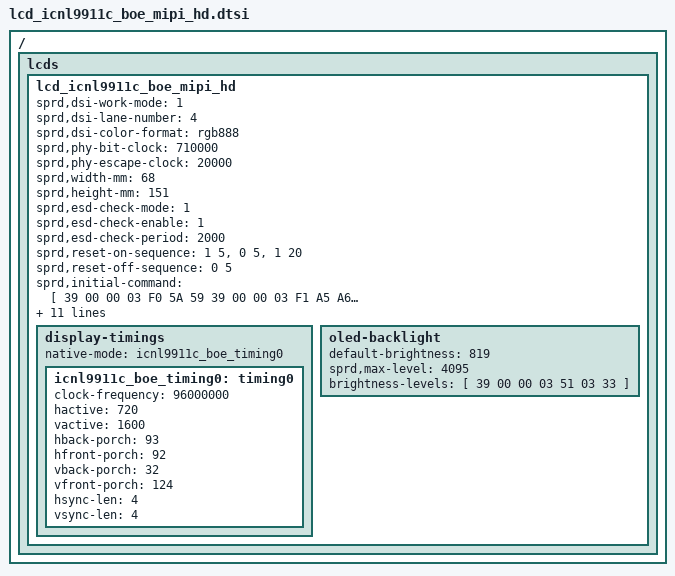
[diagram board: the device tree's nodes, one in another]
/ {
	fragment {
		target-path = "/";
		__overlay__ {
			lcds {
				lcd_icnl9911c_boe_mipi_hd: lcd_icnl9911c_boe_mipi_hd {
					sprd,dsi-work-mode = <1>; /* video burst mode*/
					sprd,dsi-lane-number = <4>;
					sprd,dsi-color-format = "rgb888";

					sprd,phy-bit-clock = <710000>;  /* kbps */
					sprd,phy-escape-clock = <20000>;/* kHz */

					sprd,width-mm = <68>;
					sprd,height-mm = <151>;

					sprd,esd-check-mode = <1>;
					sprd,esd-check-enable = <1>;
					sprd,esd-check-period = <2000>;

					sprd,reset-on-sequence = <1 5>, <0 5>, <1 20>;
					sprd,reset-off-sequence = <0 5>;

					sprd,initial-command = [
						39 00 00 03 F0 5A 59
						39 00 00 03 F1 A5 A6
						39 00 00 1F B0 83 82 05 04 02 03 04 05 11 11 11 11 00 00 00 78 00 00 0F 05 04 03 02 01 02 03 04 04 00 00
						39 00 00 21 B1 B0 02 89 80 05 00 00 79 00 00 04 08 54 00 00 00 44 40 02 01 40 02 01 40 02 01 40 02 01 00 00 00
						39 00 00 1D B4 00 01 01 05 DD DC 01 01 E3 00 00 0F 0D DD 00 00 00 00 00 00 00 00 1F FC 00 00 00 00
						39 00 00 1D B5 00 01 01 04 DD DC 01 01 E3 00 00 0E 0C DD 00 00 00 00 00 00 00 00 1F FC 00 00 00 00
						39 00 00 20 B3 02 01 01 0D 0C 26 6A 91 A2 33 44 00 26 00 18 01 02 08 20 30 2A 69 2B 00 00 20 40 08 09 22 33
						39 00 00 19 B8 55 55 55 55 00 00 55 55 55 55 00 00 00 00 00 00 00 00 00 00 00 00 00 00
						39 00 00 0E BB 01 05 09 11 0D 19 1D 55 25 69 00 21 25
						39 00 00 0F BC 00 00 00 00 02 20 FF 00 03 11 01 73 33 00
						39 00 00 0B BD E9 02 4F CF 72 A4 08 44 AE 15
						39 00 00 0B BE 6E 6E 0A 1E 0C 77 43 07 0E 0E
						39 00 00 09 BF 07 25 07 25 7F 00 11 04
						39 00 00 0A C0 10 FF FF FF FF FF 00 FF 00
						39 00 00 14 C1 C0 20 20 7C 04 5D 5C 04 2A 40 36 00 07 C0 10 FF C0 00 C0
						39 00 00 02 C2 00
						39 00 00 0C C3 06 00 FF 00 FF 00 00 81 01 00 00
						39 00 00 0B C4 84 03 2B 41 00 3C 00 03 03 3E
						39 00 00 0C C5 03 1C C0 C0 40 10 42 84 0A 12 14
						39 00 00 0B C6 89 15 22 29 29 33 64 24 08 04
						39 00 00 17 C7 F7 B2 8A 6E 3C 1B E9 3C 06 DC B3 85 DF B6 9B 75 5F 3F 1A 7E C0 00
						39 00 00 17 C8 F7 B2 8A 6E 3C 1B E9 3C 06 DC B3 85 DF B6 9B 75 5F 3F 1A 7E C0 00
						39 00 00 02 CB 00
						39 00 00 06 D0 80 0D FF 0F 61
						39 00 00 02 D2 42
						39 00 00 21 E0 30 00 80 88 11 3F 22 62 DF A0 04 CC 01 FF FA FF F0 FD DB D3 F8 AD FC FC FB FF 00 00 00 00 00 00
						39 00 00 18 E1 7C F8 CA AA AB 9B F0 0C F0 85 F0 70 E5 3E 00 8A FD F0 E0 FF 00 03 92
						39 00 00 03 F0 A5 A6
						39 00 00 03 F1 5A 59
						39 00 00 03 51 00 00
						39 00 00 02 53 2C
						39 00 00 02 55 00
						39 00 00 02 35 00
						39 78 00 01 11
						39 0A 00 01 29
						39 15 00 02 26 01
						];

					sprd,sleep-in-command = [
						39 00 00 02 26 08
						13 0A 00 01 28
						13 78 00 01 10
						];
					sprd,sleep-out-command = [
						13 78 00 01 11
						13 32 00 01 29
						39 00 00 02 26 01
						];

					sprd,cabc-off-command = [
						39 00 00 02 55 00
					];
					sprd,cabc-ui-command = [
						39 00 00 03 F0 5A 59
						39 00 00 03 F1 A5 A6
						39 00 00 21 E0 30 00 80 88 11 3F 22 62 DF A0 04 CC 01 FF FA FF F0 FD DB D3 F8 AD FC FC FB FF 00 00 00 00 00 00
						39 00 00 18 E1 7C F8 CA AA AB 9B F0 0C F0 85 F0 70 E5 3E 00 8A FD F0 E0 FF 00 03 92
						39 00 00 03 F1 5A 59
						39 00 00 03 F0 A5 A6
						39 00 00 02 55 03
					];
					sprd,cabc-still-command = [
						39 00 00 03 F0 5A 59
						39 00 00 03 F1 A5 A6
						39 00 00 21 E0 30 00 80 88 11 3F 22 62 DF A0 04 CC 01 FF FA FF F0 FD DB D3 F8 AD FC FC FB FF 00 00 00 00 00 00
						39 00 00 18 E1 7C F8 CA AA AB 9B F0 0C F0 85 F0 70 E5 3E 00 8A FD F0 E0 FF 00 03 92
						39 00 00 03 F1 5A 59
						39 00 00 03 F0 A5 A6
						39 00 00 02 55 03
					];
					sprd,cabc-moving-command = [
						39 00 00 03 F0 5A 59
						39 00 00 03 F1 A5 A6
						39 00 00 21 E0 30 00 80 88 11 3F 22 62 DF A0 04 CC 01 FF FA FF F0 FD DB D3 F8 AD FC FC FB FF 00 00 00 00 00 00
						39 00 00 18 E1 7C F8 CA AA AB 9B F0 0C F0 85 F0 70 E5 3E 00 8A FD F0 E0 FF 00 03 92
						39 00 00 03 F1 5A 59
						39 00 00 03 F0 A5 A6
						39 00 00 02 55 03
					];

					display-timings {
						native-mode = <&icnl9911c_boe_timing0>;

						icnl9911c_boe_timing0: timing0 {
							clock-frequency = <96000000>;
							hactive = <720>;
							vactive = <1600>;
							hback-porch = <93>;
							hfront-porch = <92>;
							vback-porch = <32>;
							vfront-porch = <124>;
							hsync-len = <4>;
							vsync-len = <4>;

						};
					};

					oled-backlight {
						default-brightness = <819>;
						sprd,max-level = <4095>;
						brightness-levels = [
							39 00 00 03 51 03 33
						];
					};
				};
			};
		};
	};
};
